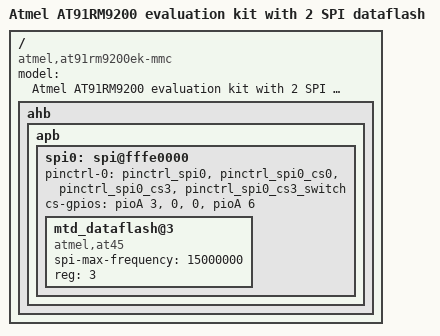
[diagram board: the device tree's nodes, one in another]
/*
 * at91rm9200ek.dts - Device Tree file for Atmel AT91RM9200 evaluation kit with
 *                    2 SPI dataflash
 *
 *  Copyright (C) 2013 Boris BREZILLON <b.brezillon@overkiz.com>
 *
 * Licensed under GPLv2 only
 */
/dts-v1/;
#include "at91rm9200ek.dts"

/ {
	model = "Atmel AT91RM9200 evaluation kit with 2 SPI dataflash";
	compatible = "atmel,at91rm9200ek-mmc", "atmel,at91rm9200ek", "atmel,at91rm9200";

	ahb {
		apb {
			spi0: spi@fffe0000 {
				pinctrl-0 = <&pinctrl_spi0 &pinctrl_spi0_cs0
					     &pinctrl_spi0_cs3
					     &pinctrl_spi0_cs3_switch>;
				cs-gpios = <&pioA 3 GPIO_ACTIVE_HIGH>, <0>,
					   <0>, <&pioA 6 GPIO_ACTIVE_HIGH>;

				mtd_dataflash@3 {
					compatible = "atmel,at45", "atmel,dataflash";
					spi-max-frequency = <15000000>;
					reg = <3>;
				};
			};
		};
	};
};
